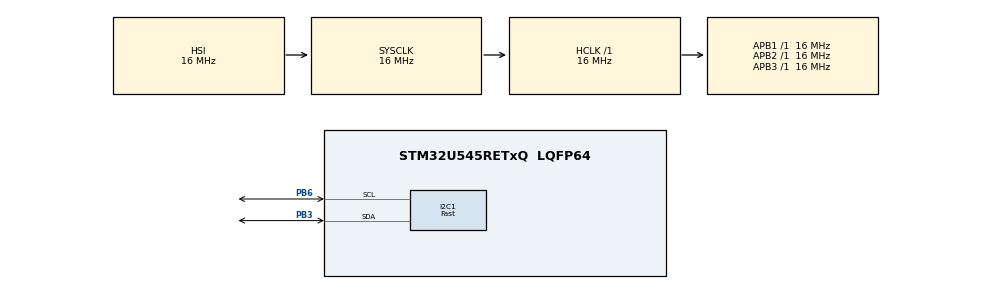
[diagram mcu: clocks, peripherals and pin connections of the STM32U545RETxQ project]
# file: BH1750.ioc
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CORTEX_M33_NS.userName=CORTEX_M33
GPDMA1.DESTINC_GPDMACH0=DMA_DINC_INCREMENTED
GPDMA1.IPHANDLE_GPDMACH0-SIMPLEREQUEST_GPDMACH0=__NULL
GPDMA1.REQUEST_GPDMACH0=GPDMA1_REQUEST_I2C1_RX
I2C1.Analog_Filter=I2C_ANALOGFILTER_ENABLE
I2C1.I2C_Speed_Mode=I2C_Fast
I2C1.Speed=200
I2C1.Timing=0x00100B3D
Mcu.Family=STM32U5
Mcu.Name=STM32U545RETxQ
Mcu.Package=LQFP64
NUCLEO-U545RE-Q.VCP=true
NVIC.GPDMA1_Channel0_IRQn=true\:0\:0\:false\:false\:true\:false\:true\:true
NVIC.I2C1_ER_IRQn=true\:0\:0\:false\:false\:true\:true\:true\:true
NVIC.I2C1_EV_IRQn=true\:0\:0\:false\:false\:true\:true\:true\:true
NVIC.PriorityGroup=NVIC_PRIORITYGROUP_4
NVIC.TIM6_IRQn=true\:0\:0\:false\:false\:true\:true\:true\:true
PB3\ (JTDO/TRACESWO).GPIO_Pu=GPIO_PULLUP
PB3\ (JTDO/TRACESWO).Mode=I2C
PB3\ (JTDO/TRACESWO).Signal=I2C1_SDA
PB6.GPIO_Pu=GPIO_PULLUP
PB6.Mode=I2C
PB6.Signal=I2C1_SCL
PWR.PowerMode=PWR_SMPS_SUPPLY
ProjectManager.HeapSize=0x200
ProjectManager.StackSize=0x400
ProjectManager.TargetToolchain=STM32CubeIDE
RCC.ADCFreq_Value=16000000
RCC.AHBFreq_Value=16000000
RCC.APB1Freq_Value=16000000
RCC.APB1TimFreq_Value=16000000
RCC.APB2Freq_Value=16000000
RCC.APB2TimFreq_Value=16000000
RCC.APB3Freq_Value=16000000
RCC.CortexFreq_Value=16000000
RCC.DACCLockSelectionVirtual=RCC_DAC1CLKSOURCE_LSI
RCC.DACCLockSelectionVirtualString=RCC_DAC1CLKSOURCE_LSI
RCC.EPOD_VALUE=16000000
RCC.HCLKFreq_Value=16000000
RCC.HSE_VALUE=16000000
RCC.HSI48_VALUE=48000000
RCC.HSI_VALUE=16000000
RCC.LSE_VALUE=32768
RCC.LSIDIV_VALUE=32000
RCC.MSIClockRange=RCC_MSIRANGE_2
RCC.MSI_VALUE=16000000
RCC.SYSCLKFreq_VALUE=16000000
RCC.SYSCLKSource=RCC_SYSCLKSOURCE_HSI
RCC.USBFreq_Value=48000000
RCC.VCOOutputFreq_Value=2064000000
TIM6.PeriodNoDither=279
TIM6.Prescaler=15999
TIM6.TIM_MasterOutputTrigger=TIM_TRGO_UPDATE
VP_GPDMA1_VS_GPDMACH0.Mode=SIMPLEREQUEST_GPDMACH0
VP_ICACHE_VS_ICACHE.Mode=DirectMappedCache
VP_LPBAMQUEUE_VS_QUEUE.Mode=QUEUEMODE
VP_MEMORYMAP_VS_MEMORYMAP.Mode=CurAppReg
VP_NUCLEO-U545RE-Q_VS_BSP_COMMON.Mode=COMMON
VP_PWR_VS_LPOM.Mode=PowerOptimisation
VP_PWR_VS_SECSignals.Mode=Security/Privilege
VP_TIM6_VS_ClockSourceINT.Mode=Enable_Timer
board=NUCLEO-U545RE-Q

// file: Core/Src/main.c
/* USER CODE BEGIN Header */
/**
  ******************************************************************************
  * @file           : main.c
  * @brief          : Main program body
  ******************************************************************************
  * @attention
  *
  * Copyright (c) 2026 STMicroelectronics.
  * All rights reserved.
  *
  * This software is licensed under terms that can be found in the LICENSE file
  * in the root directory of this software component.
  * If no LICENSE file comes with this software, it is provided AS-IS.
  *
  ******************************************************************************
  */
/* USER CODE END Header */
#include "main.h"

/* USER CODE BEGIN Includes */
#include "BH1750.h"
/* USER CODE END Includes */

COM_InitTypeDef BspCOMInit;

I2C_HandleTypeDef hi2c1;
DMA_HandleTypeDef handle_GPDMA1_Channel0;

TIM_HandleTypeDef htim6;

/* USER CODE BEGIN PV */
bh1750_t bh1750;
uint32_t last_meas_time;
float lux = 0;
/* USER CODE END PV */

void SystemClock_Config(void);
static void SystemPower_Config(void);
static void MX_GPIO_Init(void);
static void MX_GPDMA1_Init(void);
static void MX_I2C1_Init(void);
static void MX_ICACHE_Init(void);
static void MX_TIM6_Init(void);

int main(void)
{

  /* MCU Configuration--------------------------------------------------------*/

  /* Reset of all peripherals, Initializes the Flash interface and the Systick. */
  HAL_Init();

  /* Configure the System Power */
  SystemPower_Config();

  /* Configure the system clock */
  SystemClock_Config();

  /* Initialize all configured peripherals */
  MX_GPIO_Init();
  MX_GPDMA1_Init();
  MX_I2C1_Init();
  MX_ICACHE_Init();
  MX_TIM6_Init();
  /* USER CODE BEGIN 2 */
  BH1750_init(&bh1750, &hi2c1, &htim6, BH1750_ADDR_L);
  /* USER CODE END 2 */

  /* Initialize COM1 port (115200, 8 bits (7-bit data + 1 stop bit), no parity */
  BspCOMInit.BaudRate   = 115200;
  BspCOMInit.WordLength = COM_WORDLENGTH_8B;
  BspCOMInit.StopBits   = COM_STOPBITS_1;
  BspCOMInit.Parity     = COM_PARITY_NONE;
  BspCOMInit.HwFlowCtl  = COM_HWCONTROL_NONE;
  if (BSP_COM_Init(COM1, &BspCOMInit) != BSP_ERROR_NONE)
  {
    Error_Handler();
  }

  /* Infinite loop */
  /* USER CODE BEGIN WHILE */
  while (1)
  {
	  if(HAL_GetTick() - last_meas_time >= 1000){
		  BH1750_single_meas(&bh1750, BH1750_H_RES_M);
		  lux = BH1750_get_data(&bh1750);
		  last_meas_time = HAL_GetTick();
	  }

    /* USER CODE END WHILE */

  }
}

void SystemClock_Config(void)
{
  RCC_OscInitTypeDef RCC_OscInitStruct = {0};
  RCC_ClkInitTypeDef RCC_ClkInitStruct = {0};

  /** Configure the main internal regulator output voltage
  */
  if (HAL_PWREx_ControlVoltageScaling(PWR_REGULATOR_VOLTAGE_SCALE4) != HAL_OK)
  {
    Error_Handler();
  }

  /** Initializes the CPU, AHB and APB buses clocks
  */
  RCC_OscInitStruct.OscillatorType = RCC_OSCILLATORTYPE_HSI;
  RCC_OscInitStruct.HSIState = RCC_HSI_ON;
  RCC_OscInitStruct.HSICalibrationValue = RCC_HSICALIBRATION_DEFAULT;
  RCC_OscInitStruct.PLL.PLLState = RCC_PLL_NONE;
  if (HAL_RCC_OscConfig(&RCC_OscInitStruct) != HAL_OK)
  {
    Error_Handler();
  }

  /** Initializes the CPU, AHB and APB buses clocks
  */
  RCC_ClkInitStruct.ClockType = RCC_CLOCKTYPE_HCLK|RCC_CLOCKTYPE_SYSCLK
                              |RCC_CLOCKTYPE_PCLK1|RCC_CLOCKTYPE_PCLK2
                              |RCC_CLOCKTYPE_PCLK3;
  RCC_ClkInitStruct.SYSCLKSource = RCC_SYSCLKSOURCE_HSI;
  RCC_ClkInitStruct.AHBCLKDivider = RCC_SYSCLK_DIV1;
  RCC_ClkInitStruct.APB1CLKDivider = RCC_HCLK_DIV1;
  RCC_ClkInitStruct.APB2CLKDivider = RCC_HCLK_DIV1;
  RCC_ClkInitStruct.APB3CLKDivider = RCC_HCLK_DIV1;

  if (HAL_RCC_ClockConfig(&RCC_ClkInitStruct, FLASH_LATENCY_1) != HAL_OK)
  {
    Error_Handler();
  }
}

/**
  * @brief Power Configuration
  * @retval None
  */
static void SystemPower_Config(void)
{

  /*
   * Switch to SMPS regulator instead of LDO
   */
  if (HAL_PWREx_ConfigSupply(PWR_SMPS_SUPPLY) != HAL_OK)
  {
    Error_Handler();
  }
}

static void MX_GPDMA1_Init(void)
{

  /* Peripheral clock enable */
  __HAL_RCC_GPDMA1_CLK_ENABLE();

  /* GPDMA1 interrupt Init */
    HAL_NVIC_SetPriority(GPDMA1_Channel0_IRQn, 0, 0);
    HAL_NVIC_EnableIRQ(GPDMA1_Channel0_IRQn);

}

static void MX_I2C1_Init(void)
{

  hi2c1.Instance = I2C1;
  hi2c1.Init.Timing = 0x00100B3D;
  hi2c1.Init.OwnAddress1 = 0;
  hi2c1.Init.AddressingMode = I2C_ADDRESSINGMODE_7BIT;
  hi2c1.Init.DualAddressMode = I2C_DUALADDRESS_DISABLE;
  hi2c1.Init.OwnAddress2 = 0;
  hi2c1.Init.OwnAddress2Masks = I2C_OA2_NOMASK;
  hi2c1.Init.GeneralCallMode = I2C_GENERALCALL_DISABLE;
  hi2c1.Init.NoStretchMode = I2C_NOSTRETCH_DISABLE;
  if (HAL_I2C_Init(&hi2c1) != HAL_OK)
  {
    Error_Handler();
  }

  /** Configure Analogue filter
  */
  if (HAL_I2CEx_ConfigAnalogFilter(&hi2c1, I2C_ANALOGFILTER_ENABLE) != HAL_OK)
  {
    Error_Handler();
  }

  /** Configure Digital filter
  */
  if (HAL_I2CEx_ConfigDigitalFilter(&hi2c1, 0) != HAL_OK)
  {
    Error_Handler();
  }

}

static void MX_ICACHE_Init(void)
{

  /** Enable instruction cache in 1-way (direct mapped cache)
  */
  if (HAL_ICACHE_ConfigAssociativityMode(ICACHE_1WAY) != HAL_OK)
  {
    Error_Handler();
  }
  if (HAL_ICACHE_Enable() != HAL_OK)
  {
    Error_Handler();
  }

}

static void MX_TIM6_Init(void)
{

  TIM_MasterConfigTypeDef sMasterConfig = {0};

  htim6.Instance = TIM6;
  htim6.Init.Prescaler = 15999;
  htim6.Init.CounterMode = TIM_COUNTERMODE_UP;
  htim6.Init.Period = 279;
  htim6.Init.AutoReloadPreload = TIM_AUTORELOAD_PRELOAD_DISABLE;
  if (HAL_TIM_Base_Init(&htim6) != HAL_OK)
  {
    Error_Handler();
  }
  sMasterConfig.MasterOutputTrigger = TIM_TRGO_UPDATE;
  sMasterConfig.MasterSlaveMode = TIM_MASTERSLAVEMODE_DISABLE;
  if (HAL_TIMEx_MasterConfigSynchronization(&htim6, &sMasterConfig) != HAL_OK)
  {
    Error_Handler();
  }

}

static void MX_GPIO_Init(void)
{

  /* GPIO Ports Clock Enable */
  __HAL_RCC_GPIOB_CLK_ENABLE();

}

void Error_Handler(void)
{
  __disable_irq();
  while (1)
  {
  }
}
